# STM32F410Tx register map
File version: 1.0
Registers are 32-bit, read-write, reset 0x0 unless marked. A register's access mark holds for its fields unless they carry their own. Offsets are from the block's base; lines under a group give offsets from that group; [hi:lo] are bit positions; {n}, {i} and the like mark numbered series; 'fields as' and 'values as' point back to an identical list; <NAME> marks a mode.

## Memory map
0x40000C00 TIM5 — TIM
0x40001000 TIM6 — TIM
0x40002400 LPTIM1 — LPTIMER
0x40002800 RTC — Real-Time Clock
0x40002C00 WWDG — Window WATCHDOG
0x40003000 IWDG — Independent WATCHDOG
0x40004400 USART2 — Universal Synchronous Asynchronous Receiver Transmitter
0x40005400 I2C1 — Inter-integrated Circuit Interface
0x40005800 I2C2 — Inter-integrated Circuit Interface
0x40006000 FMPI2C1 — Inter-integrated Circuit Interface
0x40007000 PWR — Power Control
0x40007400 DAC — Digital to Analog Converter
0x40007400 DAC1 — Digital to Analog Converter
0x40010000 TIM1 — TIM
0x40011000 USART1 — Universal Synchronous Asynchronous Receiver Transmitter
0x40012000 ADC1 — Analog to Digital Converter
0x40013000 SPI1 — Serial Peripheral Interface
0x40013800 SYSCFG — System configuration controller
0x40013C00 EXTI — External Interrupt/Event Controller
0x40014000 TIM9 — TIM
0x40014800 TIM11 — TIM
0x40020000 GPIOA — General Purpose I/O
0x40020400 GPIOB — General Purpose I/O
0x40020800 GPIOC — General Purpose I/O
0x40021C00 GPIOH — General Purpose I/O
0x40023000 CRC — CRC calculation unit
0x40023800 RCC — Reset and Clock Control
0x40023C00 FLASH — FLASH Registers
0x40026000 DMA1
0x40026400 DMA2
0x40080000 RNG
0xE0042000 DBGMCU — Debug MCU

## Interrupts
0 WWDG — Window WatchDog Interrupt
3 RTC_WKUP (RTC) — RTC Wakeup interrupt through the EXTI line
4 FLASH — FLASH global Interrupt
5 RCC — RCC global Interrupt
6 EXTI0 (EXTI) — EXTI Line0 Interrupt
7 EXTI1 (EXTI) — EXTI Line1 Interrupt
8 EXTI2 (EXTI) — EXTI Line2 Interrupt
9 EXTI3 (EXTI) — EXTI Line3 Interrupt
10 EXTI4 (EXTI) — EXTI Line4 Interrupt
11 DMA1_Stream0 (DMA1) — DMA1 Stream 0 global Interrupt
12 DMA1_Stream1 (DMA1) — DMA1 Stream 1 global Interrupt
13 DMA1_Stream2 (DMA1) — DMA1 Stream 2 global Interrupt
14 DMA1_Stream3 (DMA1) — DMA1 Stream 3 global Interrupt
15 DMA1_Stream4 (DMA1) — DMA1 Stream 4 global Interrupt
16 DMA1_Stream5 (DMA1) — DMA1 Stream 5 global Interrupt
17 DMA1_Stream6 (DMA1) — DMA1 Stream 6 global Interrupt
18 ADC (ADC1) — ADC1 global Interrupts
23 EXTI9_5 (EXTI) — External Line[9:5] Interrupts
24 TIM1_BRK_TIM9 (TIM1, TIM9) — TIM1 Break interrupt and TIM9 global interrupt
25 TIM1_UP (TIM1) — TIM1 Update Interrupt
26 TIM1_TRG_COM_TIM11 (TIM11) — TIM1 Trigger and Commutation Interrupt and TIM11 global interrupt
27 TIM1_CC (TIM1) — TIM1 Capture Compare Interrupt
31 I2C1_EV (I2C1) — I2C1 Event Interrupt
32 I2C1_ER (I2C1) — I2C1 Error Interrupt
33 I2C2_EV (I2C2) — I2C2 Event Interrupt
34 I2C2_ER (I2C2) — I2C2 Error Interrupt
35 SPI1 — SPI1 global Interrupt
37 USART1 — USART1 global Interrupt
38 USART2 — USART2 global Interrupt
40 EXTI15_10 (EXTI) — External Line[15:10] Interrupts
41 RTC_Alarm (RTC) — RTC Alarm (A and B) through EXTI Line Interrupt
47 DMA1_Stream7 (DMA1) — DMA1 Stream7 Interrupt
50 TIM5 — TIM5 global Interrupt
54 TIM6_DAC (TIM6, DAC) — TIM6 global Interrupt and DAC Global Interrupt
56 DMA2_Stream0 (DMA2) — DMA2 Stream 0 global Interrupt
57 DMA2_Stream1 (DMA2) — DMA2 Stream 1 global Interrupt
58 DMA2_Stream2 (DMA2) — DMA2 Stream 2 global Interrupt
59 DMA2_Stream3 (DMA2) — DMA2 Stream 3 global Interrupt
60 DMA2_Stream4 (DMA2) — DMA2 Stream 4 global Interrupt
68 DMA2_Stream5 (DMA2) — DMA2 Stream 5 global interrupt
69 DMA2_Stream6 (DMA2) — DMA2 Stream 6 global interrupt
70 DMA2_Stream7 (DMA2) — DMA2 Stream 7 global interrupt
80 RNG — RNG global Interrupt
95 FMPI2C1_EV (FMPI2C1) — FMPI2C1 Event Interrupt
96 FMPI2C1_ER (FMPI2C1) — FMPI2C1 Error Interrupt
97 LPTIM1 — LPTIM1 interrupt

## TIM6 — TIM
Base 0x40001000
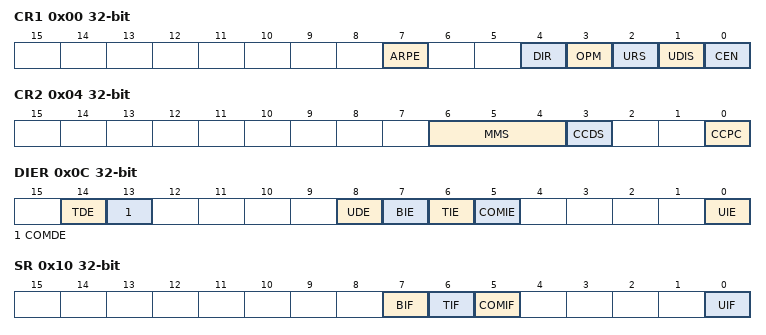
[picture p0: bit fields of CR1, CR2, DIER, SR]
0x00 CR1 — TIM control register 1
  [7] ARPE — Auto-reload preload enable
  [4] DIR — Direction
    0=UP (Timer counter counts up); 1=DOWN (Timer counter counts down)
  [3] OPM — One pulse mode
    1=SINGLE (Counter stops counting at the next update event); 0=REPETITIVE (Counter is not stopped at update event)
  [2] URS — Update request source
    0=REGULAR (Counter overflow/underflow, Setting the UG bit or Update generation through the slave mode controller generates an update request); 1=COUNTER (Only counter overflow/underflow generates an update request)
  [1] UDIS — Update disable
  [0] CEN — Counter enable
0x04 CR2 — TIM control register 2
  [6:4] MMS — MMS[2:0] bits (Master Mode Selection)
    0=RESET (UG bit from the TIMx_EGR register is used as trigger output); 1=ENABLE (Counter Enable signal (CNT_EN) is used as trigger output); 2=UPDATE (Update event is used as trigger output); 3=CC1IF (CC1 capture or a compare match is used as trigger output); {v}=OC{v-3}REF (OC{v-3}REF signal is used as trigger output) (v=4..7)
  [3] CCDS — Capture/Compare DMA Selection
    0=CC (CCx DMA request sent when CCx event occurs); 1=UPDATE (CCx DMA requests sent when update event occurs)
  [0] CCPC — Capture/Compare Preloaded Control
0x0C DIER — TIM DMA/interrupt enable register
  [14] TDE — Trigger DMA request enable
  [13] COMDE — COM DMA request enable
  [8] UDE — Update DMA request enable
  [7] BIE — Break interrupt enable
  [6] TIE — Trigger interrupt enable
  [5] COMIE — COM interrupt enable
  [0] UIE — Update interrupt enable
0x10 SR — TIM status register
  [7] BIF — Break interrupt Flag
  [6] TIF — Trigger interrupt Flag
  [5] COMIF — COM interrupt Flag
  [0] UIF — Update interrupt Flag
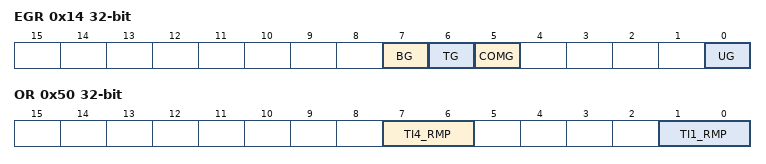
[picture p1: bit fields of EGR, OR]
0x14 EGR — TIM event generation register
  [7] BG — Break Generation
  [6] TG — Trigger Generation
  [5] COMG — Capture/Compare Control Update Generation
  [0] UG — Update Generation
0x24 CNT — TIM counter register
  [15:0] CNT — Counter Value
0x28 PSC — TIM prescaler
  [15:0] PSC — Prescaler Value
0x2C ARR — TIM auto-reload register
  [15:0] ARR — actual auto-reload Value
0x4C DMAR — TIM DMA address for full transfer
  [15:0] DMAB — DMA register for burst accesses
0x50 OR — TIM option register
  [7:6] TI4_RMP — TI4_RMP[1:0] bits (TIM5 Input 4 remap)
  [1:0] TI1_RMP — TI1_RMP[1:0] bits (TIM11 Input Capture 1 remap)
